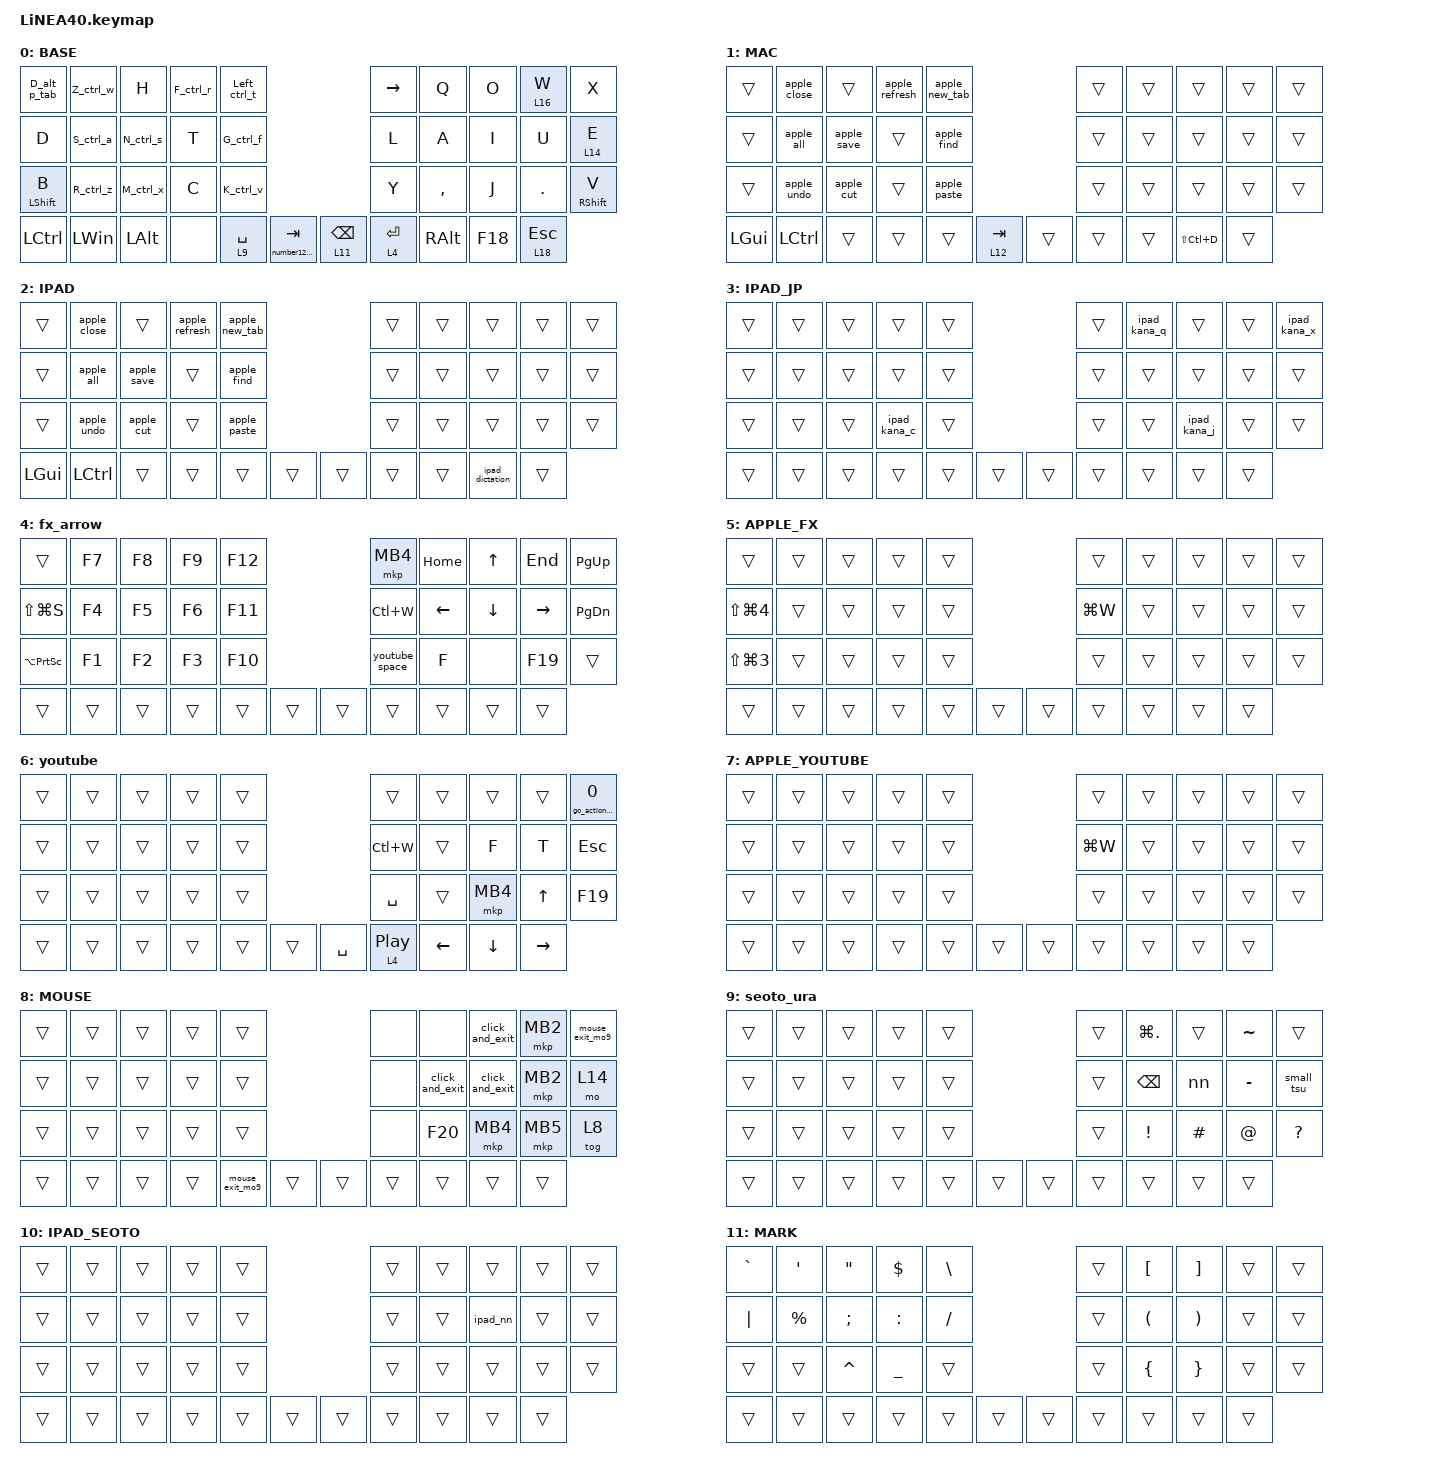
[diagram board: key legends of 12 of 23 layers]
#define ZMK_POINTING_DEFAULT_SCRL_VAL 100

#include <dt-bindings/zmk/input_transform.h>
#include <input/processors.dtsi>
#include <zephyr/dt-bindings/input/input-event-codes.h>
#include <behaviors.dtsi>
#include <dt-bindings/zmk/bt.h>
#include <dt-bindings/zmk/keys.h>
#include <dt-bindings/zmk/outputs.h>
#include <dt-bindings/zmk/pointing.h>

//mouse cursol

&mmv {
    delay-ms = <20>;
    trigger-period-ms = <5>;
    time-to-max-speed-ms = <100>;
    acceleration-exponent = <2>;
};

//mouse scroll

&msc {
    delay-ms = <3>;
    trigger-period-ms = <3>;
    time-to-max-speed-ms = <100>;
    acceleration-exponent = <0>;
};

&lt { flavor = "hold-preferred"; };

&mt { flavor = "balanced"; };

/ {
    input_processors {
        // No remainder tracking: disabled trackball motion must never accumulate.

        zip_trackball_block: zip_trackball_block {
            compatible = "zmk,input-processor-scaler";
            #input-processor-cells = <2>;
            type = <INPUT_EV_REL>;
            codes = <INPUT_REL_X INPUT_REL_Y INPUT_REL_WHEEL INPUT_REL_HWHEEL>;
        };

        zip_wheel_scaler: zip_wheel_scaler {
            compatible = "zmk,input-processor-scaler";
            #input-processor-cells = <2>;
            type = <INPUT_EV_REL>;
            codes = <INPUT_REL_WHEEL>;
            track-remainders;
        };
    };
};

&msc_input_listener {
    speed_up {
        layers = <4 20>;
        input-processors = <&zip_wheel_scaler 3 1>; //スクロールを3倍速にする
    };
};

&trackball_listener {
    // First matching override wins. Do not process the base zip_temp_layer
    // while NUMBER_SCROLL is active, including while fn/arrow keys overlay it.

    number_block {
        layers = <12>;
        input-processors = <&zip_trackball_block 0 1>;
    };

    scroller {
        layers = <14>;
        input-processors =
            // Disable horizontal scrolling; remove this scaler to restore it.,,
            <&zip_x_scaler 0 1>,
            <&zip_xy_transform INPUT_TRANSFORM_Y_INVERT>,
            <&zip_xy_to_scroll_mapper>,
            <&zip_wheel_scaler 1 20>;
    };
};

/ {
    combos {
        compatible = "zmk,combos";

        DeleteKey {
            bindings = <&kp DEL>;
            key-positions = <9 8>;
            layers = <0 12 1 2 13 3>;
        };

        InsertKey {
            bindings = <&kp INS>;
            key-positions = <6 7>;
            layers = <0 1 2 3>;
        };

        IMEON {
            bindings = <&IME_ON_mouseout>;
            key-positions = <17 16>;
            timeout-ms = <80>;
        };

        CenterClick {
            bindings = <&mkp MB3>;
            key-positions = <18 17>;
            layers = <8>;
        };

        IMEOFF {
            bindings = <&IME_OFF_mouseout>;
            key-positions = <13 12>;
            timeout-ms = <80>;
        };

        CtrlEnter {
            bindings = <&kp LC(ENTER)>;
            key-positions = <29 28>;
            layers = <0 1 2 3>;
        };

        esc {
            bindings = <&kp ESCAPE>;
            key-positions = <0 1>;
            layers = <0 22 1 2 3>;
        };

        DeleteKey2 {
            bindings = <&kp DEL>;
            key-positions = <16 9>;
            layers = <0 12 1 2 13 3>;
        };

        window_minimum {
            bindings = <&window_minimum>;
            key-positions = <31 32>;
            layers = <0>;
        };

        apple_window_minimum {
            bindings = <&kp LG(M)>;
            key-positions = <31 32>;
            layers = <1 2 3>;
        };

        CenterClick2 {
            bindings = <&mkp MB3>;
            key-positions = <7 8>;
            layers = <8>;
        };

        to_browsing {
            bindings = <&to2_youtube>;
            key-positions = <38 39 40>;
            layers = <0 8 1 2 3>;
            timeout-ms = <150>;
        };

        L1_home {
            bindings = <&kp HOME>;
            key-positions = <8 9>;
            layers = <4 20 5 21>;
        };

        L1_end {
            bindings = <&kp END>;
            key-positions = <18 19>;
            layers = <4 20 5 21>;
        };

        L1_less {
            bindings = <&kp LESS_THAN>;
            key-positions = <7 16>;
            layers = <4 20 5 21>;
        };

        L1_greater {
            bindings = <&kp GREATER_THAN>;
            key-positions = <7 18>;
            layers = <4 20 5 21>;
        };

        L2_greater {
            bindings = <&kp GREATER_THAN>;
            key-positions = <28 40>;
            layers = <6 7>;
        };

        L2_less {
            bindings = <&kp LESS_THAN>;
            key-positions = <28 38>;
            layers = <6 7>;
        };

        to_browsing2 {
            bindings = <&none>;
            key-positions = <38 39 40>;
            layers = <6 7>;
        };
    };

    behaviors {
        ipad_kana_c: ipad_kana_c {
            compatible = "zmk,behavior-mod-morph";
            #binding-cells = <0>;
            bindings = <&kp K>, <&kp C>;
            mods = <(MOD_LCTL | MOD_LSFT | MOD_LALT | MOD_LGUI |
                      MOD_RCTL | MOD_RSFT | MOD_RALT | MOD_RGUI)>;
            keep-mods = <(MOD_LCTL | MOD_LSFT | MOD_LALT | MOD_LGUI |
                           MOD_RCTL | MOD_RSFT | MOD_RALT | MOD_RGUI)>;
        };

        ipad_kana_x: ipad_kana_x {
            compatible = "zmk,behavior-mod-morph";
            #binding-cells = <0>;
            bindings = <&ipad_romaji_ya>, <&kp X>;
            mods = <(MOD_LCTL | MOD_LSFT | MOD_LALT | MOD_LGUI |
                      MOD_RCTL | MOD_RSFT | MOD_RALT | MOD_RGUI)>;
            keep-mods = <(MOD_LCTL | MOD_LSFT | MOD_LALT | MOD_LGUI |
                           MOD_RCTL | MOD_RSFT | MOD_RALT | MOD_RGUI)>;
        };

        ipad_kana_j: ipad_kana_j {
            compatible = "zmk,behavior-mod-morph";
            #binding-cells = <0>;
            bindings = <&ipad_romaji_yu>, <&kp J>;
            mods = <(MOD_LCTL | MOD_LSFT | MOD_LALT | MOD_LGUI |
                      MOD_RCTL | MOD_RSFT | MOD_RALT | MOD_RGUI)>;
            keep-mods = <(MOD_LCTL | MOD_LSFT | MOD_LALT | MOD_LGUI |
                           MOD_RCTL | MOD_RSFT | MOD_RALT | MOD_RGUI)>;
        };

        ipad_kana_q: ipad_kana_q {
            compatible = "zmk,behavior-mod-morph";
            #binding-cells = <0>;
            bindings = <&ipad_romaji_yo>, <&kp Q>;
            mods = <(MOD_LCTL | MOD_LSFT | MOD_LALT | MOD_LGUI |
                      MOD_RCTL | MOD_RSFT | MOD_RALT | MOD_RGUI)>;
            keep-mods = <(MOD_LCTL | MOD_LSFT | MOD_LALT | MOD_LGUI |
                           MOD_RCTL | MOD_RSFT | MOD_RALT | MOD_RGUI)>;
        };

        apple_paste: apple_paste {
            compatible = "zmk,behavior-mod-morph";
            #binding-cells = <0>;
            bindings = <&kp K>, <&kp LG(V)>;
            mods = <(MOD_LGUI | MOD_RGUI)>;
            keep-mods = <(MOD_LGUI | MOD_RGUI)>;
        };

        apple_cut: apple_cut {
            compatible = "zmk,behavior-mod-morph";
            #binding-cells = <0>;
            bindings = <&kp M>, <&kp LG(X)>;
            mods = <(MOD_LGUI | MOD_RGUI)>;
            keep-mods = <(MOD_LGUI | MOD_RGUI)>;
        };

        apple_undo: apple_undo {
            compatible = "zmk,behavior-mod-morph";
            #binding-cells = <0>;
            bindings = <&kp R>, <&kp LG(Z)>;
            mods = <(MOD_LGUI | MOD_RGUI)>;
            keep-mods = <(MOD_LGUI | MOD_RGUI)>;
        };

        apple_all: apple_all {
            compatible = "zmk,behavior-mod-morph";
            #binding-cells = <0>;
            bindings = <&kp S>, <&kp LG(A)>;
            mods = <(MOD_LGUI | MOD_RGUI)>;
            keep-mods = <(MOD_LGUI | MOD_RGUI)>;
        };

        apple_save: apple_save {
            compatible = "zmk,behavior-mod-morph";
            #binding-cells = <0>;
            bindings = <&kp N>, <&kp LG(S)>;
            mods = <(MOD_LGUI | MOD_RGUI)>;
            keep-mods = <(MOD_LGUI | MOD_RGUI)>;
        };

        apple_new_tab: apple_new_tab {
            compatible = "zmk,behavior-mod-morph";
            #binding-cells = <0>;
            bindings = <&kp LEFT>, <&kp LG(T)>;
            mods = <(MOD_LGUI | MOD_RGUI)>;
            keep-mods = <(MOD_LGUI | MOD_RGUI)>;
        };

        apple_close: apple_close {
            compatible = "zmk,behavior-mod-morph";
            #binding-cells = <0>;
            bindings = <&kp Z>, <&kp LG(W)>;
            mods = <(MOD_LGUI | MOD_RGUI)>;
            keep-mods = <(MOD_LGUI | MOD_RGUI)>;
        };

        apple_refresh: apple_refresh {
            compatible = "zmk,behavior-mod-morph";
            #binding-cells = <0>;
            bindings = <&kp F>, <&kp LG(R)>;
            mods = <(MOD_LGUI | MOD_RGUI)>;
            keep-mods = <(MOD_LGUI | MOD_RGUI)>;
        };

        apple_find: apple_find {
            compatible = "zmk,behavior-mod-morph";
            #binding-cells = <0>;
            bindings = <&kp G>, <&kp LG(F)>;
            mods = <(MOD_LGUI | MOD_RGUI)>;
            keep-mods = <(MOD_LGUI | MOD_RGUI)>;
        };


        W_lt: W_lt {
            compatible = "zmk,behavior-hold-tap";
            label = "W_LT";
            #binding-cells = <2>;
            bindings = <&mo>, <&kp>;

            flavor = "balanced";
            tapping-term-ms = <200>;
        };

        // Keep only left-click available briefly after leaving MOUSE.

        sl_mouse: sticky_layer_for_mouse {
            compatible = "zmk,behavior-sticky-key";
            #binding-cells = <1>;
            bindings = <&mo>;
            release-after-ms = <200>;
            quick-release;
            ignore-modifiers;
        };

        re_kp: sensor_rotate_kp {
            compatible = "zmk,behavior-sensor-rotate-var";
            #sensor-binding-cells = <2>;
            bindings = <&kp>, <&kp>;
        };

        mouse_scrl: mouse_wheel_scrl {
            compatible = "zmk,behavior-sensor-rotate-var";
            #sensor-binding-cells = <2>;
            bindings = <&msc>, <&msc>;

            tap-ms = <20>;
        };

        D_alt_p_tab: D_alt_p_tab {
            compatible = "zmk,behavior-mod-morph";
            label = "D_ALT_P_TAB";
            bindings = <&win_p_tab>, <&kp TAB>;

            #binding-cells = <0>;
            mods = <(MOD_LALT|MOD_RALT)>;
            keep-mods = <(MOD_LALT|MOD_RALT)>;
        };

        win_p_tab: win_p_tab {
            compatible = "zmk,behavior-mod-morph";
            label = "WIN_P_TAB";
            bindings = <&kp P>, <&kp TAB>;

            #binding-cells = <0>;
            mods = <(MOD_RGUI|MOD_LGUI)>;
            keep-mods = <(MOD_LGUI|MOD_RGUI)>;
        };

        K_ctrl_v: K_ctrl_v {
            compatible = "zmk,behavior-mod-morph";
            label = "K_CTRL_V";
            bindings = <&kp K>, <&kp LC(V)>;

            #binding-cells = <0>;
            mods = <(MOD_LCTL)>;
            keep-mods = <(MOD_LCTL)>;
        };

        M_ctrl_x: M_ctrl_x {
            compatible = "zmk,behavior-mod-morph";
            label = "M_CTRL_X";
            bindings = <&kp M>, <&kp LC(X)>;

            #binding-cells = <0>;
            mods = <(MOD_LCTL)>;
            keep-mods = <(MOD_LCTL)>;
        };

        R_ctrl_z: R_ctrl_z {
            compatible = "zmk,behavior-mod-morph";
            label = "R_CTRL_Z";
            bindings = <&kp R>, <&kp LC(Z)>;

            #binding-cells = <0>;
            mods = <(MOD_LCTL)>;
            keep-mods = <(MOD_LCTL)>;
        };

        S_ctrl_a: S_ctrl_a {
            compatible = "zmk,behavior-mod-morph";
            label = "S_CTRL_A";
            bindings = <&kp S>, <&kp LC(A)>;

            #binding-cells = <0>;
            mods = <(MOD_LCTL)>;
            keep-mods = <(MOD_LCTL)>;
        };

        N_ctrl_s: N_ctrl_s {
            compatible = "zmk,behavior-mod-morph";
            label = "N_CTRL_S";
            bindings = <&kp N>, <&kp LC(S)>;

            #binding-cells = <0>;
            mods = <(MOD_LCTL)>;
            keep-mods = <(MOD_LCTL)>;
        };

        Left_ctrl_t: Left_ctrl_t {
            compatible = "zmk,behavior-mod-morph";
            label = "LEFT_CTRL_T";
            bindings = <&kp LEFT>, <&kp LC(T)>;

            #binding-cells = <0>;
            mods = <(MOD_LCTL)>;
            keep-mods = <(MOD_LCTL)>;
        };

        Z_ctrl_w: Z_ctrl_w {
            compatible = "zmk,behavior-mod-morph";
            label = "Z_CTRL_W";
            bindings = <&kp Z>, <&kp LC(W)>;

            #binding-cells = <0>;
            mods = <(MOD_LCTL)>;
            keep-mods = <(MOD_LCTL)>;
        };

        F_ctrl_r: F_ctrl_r {
            compatible = "zmk,behavior-mod-morph";
            label = "F_CTRL_R";
            bindings = <&kp F>, <&kp LC(R)>;

            #binding-cells = <0>;
            mods = <(MOD_LCTL)>;
            keep-mods = <(MOD_LCTL)>;
        };

        G_ctrl_f: G_ctrl_f {
            compatible = "zmk,behavior-mod-morph";
            label = "G_CTRL_F";
            bindings = <&kp G>, <&kp LC(F)>;

            #binding-cells = <0>;
            mods = <(MOD_LCTL)>;
            keep-mods = <(MOD_LCTL)>;
        };

        layer_off: layer_off {
            compatible = "zmk,behavior-toggle-layer";
            label = "LAYER_OFF";
            #binding-cells = <1>;
            toggle-mode = "off";
        };

        layer_on: layer_on {
            compatible = "zmk,behavior-toggle-layer";
            #binding-cells = <1>;
            toggle-mode = "on";
        };

        win_arrow_left: win_arrow_left {
            compatible = "zmk,behavior-mod-morph";
            label = "WIN_ARROW_LEFT";
            bindings = <&win_start_left>, <&kp LEFT>;

            #binding-cells = <0>;
            mods = <(MOD_LGUI)>;
            keep-mods = <(MOD_LGUI)>;
        };

        win_arrow_down: win_arrow_down {
            compatible = "zmk,behavior-mod-morph";
            label = "WIN_ARROW_DOWN";
            bindings = <&win_start_down>, <&kp DOWN>;

            #binding-cells = <0>;
            mods = <(MOD_LGUI)>;
            keep-mods = <(MOD_LGUI)>;
        };

        win_arrow_up: win_arrow_up {
            compatible = "zmk,behavior-mod-morph";
            label = "WIN_ARROW_UP";
            bindings = <&win_start_up>, <&kp UP>;

            #binding-cells = <0>;
            mods = <(MOD_LGUI)>;
            keep-mods = <(MOD_LGUI)>;
        };

        win_arrow_right: win_arrow_right {
            compatible = "zmk,behavior-mod-morph";
            label = "WIN_ARROW_RIGHT";
            bindings = <&win_start_right>, <&kp RIGHT>;

            #binding-cells = <0>;
            mods = <(MOD_LGUI)>;
            keep-mods = <(MOD_LGUI)>;
        };

        number12_lt: number12_lt {
            compatible = "zmk,behavior-hold-tap";
            label = "NUMBER12_LT";
            bindings = <&number12_hold>, <&kp>;

            #binding-cells = <2>;
            tapping-term-ms = <200>;
        };
    };

    macros {
        // A profile choice starts at that device's base. BT2 and BT3 use the Windows base.
        select_profile: select_profile {
            compatible = "zmk,behavior-macro-two-param";
            #binding-cells = <2>;
            wait-ms = <0>;
            tap-ms = <0>;
            bindings =
                <&macro_press>,
                <&macro_param_2to1 &to 0>,
                <&macro_param_1to2 &bt BT_SEL 0>;
        };

        // Clear ordinary layers in descending order. Conditional overlays follow those layers.
        // Keep the Mac/iPad base and iPad Japanese overlays (1–3) active.
        go_action_layer: go_action_layer {
            compatible = "zmk,behavior-macro-one-param";
            #binding-cells = <1>;
            wait-ms = <0>;
            tap-ms = <0>;
            bindings =
                <&macro_press>,
                <&layer_off 22 &layer_off 20 &layer_off 19 &layer_off 18>,
                <&layer_off 16 &layer_off 15 &layer_off 14 &layer_off 12>,
                <&layer_off 11 &layer_off 9 &layer_off 8 &layer_off 6 &layer_off 4>,
                <&macro_param_1to1 &layer_on 0>;
        };

        // Hold MB1 until release for dragging, then return to BASE.

        click_and_exit: click_and_exit {
            compatible = "zmk,behavior-macro";
            #binding-cells = <0>;
            label = "CLICK_AND_EXIT";
            wait-ms = <0>;
            tap-ms = <0>;
            bindings =
                <&macro_press>,
                <&mkp MB1>,
                <&macro_pause_for_release>,
                <&macro_release>,
                <&mkp MB1>,
                <&macro_press>,
                <&layer_off 22 &layer_off 20 &layer_off 19 &layer_off 18>,
                <&layer_off 16 &layer_off 15 &layer_off 14 &layer_off 12>,
                <&layer_off 11 &layer_off 9 &layer_off 8 &layer_off 6 &layer_off 4>,
                <&macro_tap &sl_mouse 19>;
        };

        nn: nn {
            compatible = "zmk,behavior-macro";
            #binding-cells = <0>;
            bindings = <&kp V &kp N>;
            label = "NN";
        };

        // Queue both letters without a wait that would let the next key overtake them.
        ipad_romaji_ya: ipad_romaji_ya {
            compatible = "zmk,behavior-macro";
            #binding-cells = <0>;
            wait-ms = <0>;
            tap-ms = <0>;
            bindings = <&kp Y &kp A>;
        };

        ipad_romaji_yu: ipad_romaji_yu {
            compatible = "zmk,behavior-macro";
            #binding-cells = <0>;
            wait-ms = <0>;
            tap-ms = <0>;
            bindings = <&kp Y &kp U>;
        };

        ipad_romaji_yo: ipad_romaji_yo {
            compatible = "zmk,behavior-macro";
            #binding-cells = <0>;
            wait-ms = <0>;
            tap-ms = <0>;
            bindings = <&kp Y &kp O>;
        };

        ipad_nn: ipad_nn {
            compatible = "zmk,behavior-macro";
            #binding-cells = <0>;
            bindings = <&kp N &kp N>;
        };

        ipad_dictation: ipad_dictation {
            compatible = "zmk,behavior-macro";
            #binding-cells = <0>;
            wait-ms = <30>;
            tap-ms = <30>;
            bindings = <&macro_press &kp GLOBE>,
                       <&macro_tap &kp D>,
                       <&macro_release &kp GLOBE>;
        };

        small_tsu: small_tsu {
            compatible = "zmk,behavior-macro";
            #binding-cells = <0>;
            bindings = <&kp L &kp T &kp U>;
            label = "SMALL_TSU";
        };

        sleep: sleep {
            compatible = "zmk,behavior-macro";
            #binding-cells = <0>;
            bindings = <&kp LG(X) &kp U &kp S>;
            label = "SLEEP";
            wait-ms = <200>;
            tap-ms = <40>;
        };

        IME_ON_mouseout: IME_ON {
            compatible = "zmk,behavior-macro";
            #binding-cells = <0>;
            bindings = <&kp LANG1 &layer_on 3 &go_action_layer 0>;
            label = "IME_ON";
        };

        IME_OFF_mouseout: IME_OFF {
            compatible = "zmk,behavior-macro";
            #binding-cells = <0>;
            bindings = <&layer_off 3 &kp LANGUAGE_2 &go_action_layer 0>;
            label = "IME_OFF";
        };

        window_minimum: window_minimum {
            compatible = "zmk,behavior-macro";
            #binding-cells = <0>;
            bindings = <&kp LA(SPACE) &kp N>;
            label = "WINDOW_MINIMUM";
            wait-ms = <50>;
            tap-ms = <50>;
        };

        mouse_exit_mo9: mouse_exit_mo9 {
            compatible = "zmk,behavior-macro";
            #binding-cells = <0>;
            bindings =
                <&layer_off 8>,
                <&macro_press>,
                <&mo 15>,
                <&macro_pause_for_release>,
                <&macro_release>,
                <&mo 15>,
                <&macro_tap>,
                <&layer_off 8>;

            label = "MOUSE_EXIT_MO9";
            wait-ms = <0>;
            tap-ms = <0>;
        };

        win_start_left: win_start_left {
            compatible = "zmk,behavior-macro";
            #binding-cells = <0>;
            bindings = <&macro_press>, <&kp LEFT_GUI>, <&macro_tap>, <&kp LEFT>;

            label = "WIN_START_LEFT";
            wait-ms = <30>;
            tap-ms = <30>;
        };

        win_start_down: win_start_down {
            compatible = "zmk,behavior-macro";
            #binding-cells = <0>;
            bindings = <&macro_press>, <&kp LEFT_GUI>, <&macro_tap>, <&kp DOWN>;

            label = "WIN_START_DOWN";
            wait-ms = <30>;
            tap-ms = <30>;
        };

        win_start_up: win_start_up {
            compatible = "zmk,behavior-macro";
            #binding-cells = <0>;
            bindings = <&macro_press>, <&kp LEFT_GUI>, <&macro_tap>, <&kp UP>;

            label = "WIN_START_UP";
            wait-ms = <30>;
            tap-ms = <30>;
        };

        win_start_right: win_start_right {
            compatible = "zmk,behavior-macro";
            #binding-cells = <0>;
            bindings =
                <&macro_press>,
                <&kp LEFT_GUI>,
                <&macro_tap>,
                <&kp RIGHT>;

            label = "WIN_START_RIGHT";
            wait-ms = <30>;
            tap-ms = <30>;
        };

        number12_hold: number12_hold {
            compatible = "zmk,behavior-macro";
            #binding-cells = <0>;
            bindings =
                <&macro_press>,
                <&mo 12>,
                <&macro_pause_for_release>,
                <&macro_release>,
                <&kp LEFT_GUI &mo 12>;

            label = "NUMBER12_HOLD";
            wait-ms = <0>;
            tap-ms = <0>;
        };

        youtube_space: youtube_space {
            compatible = "zmk,behavior-macro";
            #binding-cells = <0>;
            bindings = <&kp F19 &kp SPACE>;
            label = "YOUTUBE_SPACE";
            wait-ms = <250>;
            tap-ms = <40>;
        };

        to2_youtube: to2_youtube {
            compatible = "zmk,behavior-macro";
            #binding-cells = <0>;
            bindings =
                <&macro_press>,
                <&layer_off 22 &layer_off 20 &layer_off 19 &layer_off 18>,
                <&layer_off 16 &layer_off 15 &layer_off 14 &layer_off 12>,
                <&layer_off 11 &layer_off 9 &layer_off 8 &layer_off 6 &layer_off 4>,
                <&layer_on 6>,
                <&macro_tap &kp F19>;
            label = "TO2_YOUTUBE";
        };
    };

    conditional_layers {
        compatible = "zmk,conditional-layers";

        // Keep the Japanese overlay only when explicitly enabled and iPad is the base.
        // The shared IME combo can then be used even while a mouse layer is active.
        ipad_japanese_only {
            if-layers = <2 3>;
            then-layer = <3>;
        };

        mac_apple_fx {
            if-layers = <1 4>;
            then-layer = <5>;
        };

        ipad_apple_fx {
            if-layers = <2 4>;
            then-layer = <5>;
        };

        mac_apple_youtube {
            if-layers = <1 6>;
            then-layer = <7>;
        };

        ipad_apple_youtube {
            if-layers = <2 6>;
            then-layer = <7>;
        };

        mac_apple_browser {
            if-layers = <1 16>;
            then-layer = <17>;
        };

        ipad_apple_browser {
            if-layers = <2 16>;
            then-layer = <17>;
        };

        mac_apple_fx_number {
            if-layers = <1 20>;
            then-layer = <21>;
        };

        ipad_apple_fx_number {
            if-layers = <2 20>;
            then-layer = <21>;
        };

        ipad_seoto {
            if-layers = <2 9>;
            then-layer = <10>;
        };

        mac_number {
            if-layers = <1 12>;
            then-layer = <13>;
        };
    };

    keymap {
        compatible = "zmk,keymap";

        default_layer {
            display-name = "BASE";
            bindings = <
&D_alt_p_tab      &Z_ctrl_w     &kp H         &F_ctrl_r  &Left_ctrl_t                                        &kp RIGHT    &kp Q      &kp O          &W_lt 16 W  &kp X
&kp D             &S_ctrl_a     &N_ctrl_s     &kp T      &G_ctrl_f                                           &kp L        &kp A      &kp I          &kp U       &lt 14 E
&mt LEFT_SHIFT B  &R_ctrl_z     &M_ctrl_x     &kp C      &K_ctrl_v                                           &kp Y        &kp COMMA  &kp J          &kp DOT     &mt RIGHT_SHIFT V
&kp LCTRL         &kp LEFT_WIN  &kp LEFT_ALT  &none      &lt 9 SPACE   &number12_lt 0 TAB    &lt 11 BACKSPACE  &lt 4 ENTER             &kp RIGHT_ALT  &kp F18     &lt 18 ESC
            >;

            sensor-bindings = <&mouse_scrl SCRL_DOWN SCRL_UP>;
        };

        mac_base {
            display-name = "MAC";
            bindings = <
                &trans  &apple_close   &trans        &apple_refresh  &apple_new_tab    &trans  &trans  &trans  &trans  &trans
                &trans  &apple_all     &apple_save   &trans          &apple_find       &trans  &trans  &trans  &trans  &trans
                &trans  &apple_undo    &apple_cut    &trans          &apple_paste      &trans  &trans  &trans  &trans  &trans
                &kp LGUI &kp LCTRL     &trans        &trans          &trans  &lt 12 TAB  &trans  &trans  &trans  &kp LS(LC(D))  &trans
            >;
        };

        ipad_base {
            display-name = "IPAD";
            bindings = <
                &trans  &apple_close   &trans        &apple_refresh  &apple_new_tab    &trans  &trans  &trans  &trans  &trans
                &trans  &apple_all     &apple_save   &trans          &apple_find       &trans  &trans  &trans  &trans  &trans
                &trans  &apple_undo    &apple_cut    &trans          &apple_paste      &trans  &trans  &trans  &trans  &trans
                &kp LGUI &kp LCTRL     &trans        &trans          &trans  &trans  &trans  &trans  &trans  &ipad_dictation  &trans
            >;
        };

        ipad_japanese {
            display-name = "IPAD_JP";
            bindings = <
                &trans  &trans  &trans  &trans         &trans  &trans  &ipad_kana_q  &trans        &trans  &ipad_kana_x
                &trans  &trans  &trans  &trans         &trans  &trans  &trans        &trans        &trans  &trans
                &trans  &trans  &trans  &ipad_kana_c   &trans  &trans  &trans        &ipad_kana_j  &trans  &trans
                &trans  &trans  &trans  &trans         &trans  &trans  &trans        &trans        &trans  &trans  &trans
            >;
        };

        fx_arrow {
            display-name = "fx_arrow";
            bindings = <
&trans               &kp F7  &kp F8  &kp F9  &kp F12                    &mkp MB4   &kp HOME        &kp UP_ARROW    &kp END          &kp PAGE_UP
&kp LS(LG(S))        &kp F4  &kp F5  &kp F6  &kp F11                    &kp LC(W)  &kp LEFT_ARROW  &kp DOWN_ARROW  &kp RIGHT_ARROW  &kp PAGE_DOWN
&kp LA(PRINTSCREEN)  &kp F1  &kp F2  &kp F3  &kp F10                    &youtube_space  &kp F           &none           &kp F19          &trans
&trans               &trans  &trans  &trans  &trans   &trans    &trans  &trans                     &trans          &trans           &trans
            >;

            sensor-bindings = <&mouse_scrl SCRL_RIGHT SCRL_LEFT>;
        };

        apple_fx_arrow {
            display-name = "APPLE_FX";
            bindings = <
                &trans             &trans  &trans  &trans  &trans     &trans  &trans  &trans  &trans  &trans
                &kp LS(LG(N4))     &trans  &trans  &trans  &trans     &kp LG(W)  &trans  &trans  &trans  &trans
                &kp LS(LG(N3))     &trans  &trans  &trans  &trans     &trans  &trans  &trans  &trans  &trans
                &trans             &trans  &trans  &trans  &trans  &trans  &trans  &trans  &trans  &trans  &trans
            >;
        };

        youtube {
            display-name = "youtube";
            bindings = <
&trans  &trans  &trans  &trans  &trans                       &trans              &trans  &trans          &trans          &go_action_layer 0
&trans  &trans  &trans  &trans  &trans                       &kp LC(W)           &trans  &kp F           &kp T           &kp ESCAPE
&trans  &trans  &trans  &trans  &trans                       &kp SPACE           &trans  &mkp MB4        &kp UP_ARROW    &kp F19
&trans  &trans  &trans  &trans  &trans  &trans    &kp SPACE  &lt 4 C_PLAY_PAUSE          &kp LEFT_ARROW  &kp DOWN_ARROW  &kp RIGHT_ARROW
            >;

            // Keep vertical scrolling when entering the function layer from YouTube.
            sensor-bindings = <&mouse_scrl SCRL_DOWN SCRL_UP>;
        };

        apple_youtube {
            display-name = "APPLE_YOUTUBE";
            bindings = <
                &trans  &trans  &trans  &trans  &trans  &trans  &trans  &trans  &trans  &trans
                &trans  &trans  &trans  &trans  &trans  &kp LG(W)  &trans  &trans  &trans  &trans
                &trans  &trans  &trans  &trans  &trans  &trans  &trans  &trans  &trans  &trans
                &trans  &trans  &trans  &trans  &trans  &trans  &trans  &trans  &trans  &trans  &trans
            >;
        };

        mouse {
            display-name = "MOUSE";
            bindings = <
&trans  &trans  &trans  &trans  &trans                             &none   &none            &click_and_exit  &mkp MB2  &mouse_exit_mo9
&trans  &trans  &trans  &trans  &trans                             &none   &click_and_exit  &click_and_exit  &mkp MB2  &mo 14
&trans  &trans  &trans  &trans  &trans                             &none   &kp F20          &mkp MB4         &mkp MB5  &tog 8
&trans  &trans  &trans  &trans  &mouse_exit_mo9  &trans    &trans  &trans                   &trans           &trans    &trans
            >;
        };

        seoto_ura {
            display-name = "seoto_ura";
            bindings = <
&trans  &trans  &trans  &trans  &trans                    &trans  &kp LG(PERIOD)   &trans    &kp TILDE    &trans
&trans  &trans  &trans  &trans  &trans                    &trans  &kp BACKSPACE    &nn       &kp MINUS    &small_tsu
&trans  &trans  &trans  &trans  &trans                    &trans  &kp EXCLAMATION  &kp HASH  &kp AT_SIGN  &kp QMARK
&trans  &trans  &trans  &trans  &trans  &trans    &trans  &trans                   &trans    &trans       &trans
            >;
        };

        ipad_seoto {
            display-name = "IPAD_SEOTO";
            bindings = <
                &trans  &trans  &trans  &trans  &trans  &trans  &trans  &trans  &trans  &trans
                &trans  &trans  &trans  &trans  &trans  &trans  &trans  &ipad_nn  &trans  &trans
                &trans  &trans  &trans  &trans  &trans  &trans  &trans  &trans  &trans  &trans
                &trans  &trans  &trans  &trans  &trans  &trans  &trans  &trans  &trans  &trans  &trans
            >;
        };

        mark {
            display-name = "MARK";
            bindings = <
&kp GRAVE  &kp SINGLE_QUOTE  &kp DOUBLE_QUOTES  &kp DOLLAR  &kp BACKSLASH                    &trans  &kp LEFT_BRACKET      &kp RIGHT_BRACKET      &trans  &trans
&kp PIPE   &kp PERCENT       &kp SEMI           &kp COLON   &kp SLASH                        &trans  &kp LEFT_PARENTHESIS  &kp RIGHT_PARENTHESIS  &trans  &trans
&trans     &trans            &kp CARET          &kp UNDER   &trans                           &trans  &kp LEFT_BRACE        &kp RIGHT_BRACE        &trans  &trans
&trans     &trans            &trans             &trans      &trans         &trans    &trans  &trans                        &trans                 &trans  &trans
            >;

            sensor-bindings = <&re_kp C_VOLUME_DOWN C_VOLUME_UP>;
        };

        number_scroll {
            display-name = "NUMBER_SCROLL";
            bindings = <
&trans    &kp LC(LG(LEFT_ARROW))  &win_arrow_up    &kp LC(LG(RIGHT_ARROW))  &trans                    &kp KP_SLASH     &kp NUMBER_7  &kp NUMBER_8  &kp NUMBER_9  &kp KP_MINUS
&trans    &win_arrow_left         &win_arrow_down  &win_arrow_right         &trans                    &kp KP_MULTIPLY  &kp NUMBER_4  &kp NUMBER_5  &kp NUMBER_6  &kp KP_PLUS
&kp HOME  &kp PAGE_DOWN           &kp END          &kp PAGE_UP              &trans                    &kp UNDER        &kp NUMBER_1  &kp NUMBER_2  &kp NUMBER_3  &kp ENTER
&trans    &trans                  &trans           &trans                   &trans  &trans    &trans  &lt 20 NUMBER_0                &kp NUMBER_0  &kp DOT       &kp EQUAL
            >;

            sensor-bindings = <&inc_dec_kp DOWN_ARROW UP_ARROW>;
        };

        // The four placement chords are assigned in macOS App Shortcuts.
        mac_number {
            display-name = "MAC_NUMBER";
            bindings = <
                &trans  &kp LC(LEFT)  &kp LC(LA(LG(UP)))  &kp LC(RIGHT)  &trans  &trans  &trans  &trans  &trans  &trans
                &trans  &kp LC(LA(LG(LEFT)))  &kp LC(LA(LG(DOWN)))  &kp LC(LA(LG(RIGHT)))  &trans  &trans  &trans  &trans  &trans  &trans
                &trans  &trans  &trans  &trans  &trans  &trans  &trans  &trans  &trans  &trans
                &trans  &trans  &trans  &trans  &trans  &trans  &trans  &trans  &trans  &trans  &trans
            >;
        };

        trackball_scroll {
            display-name = "trackball_scroll";
            bindings = <
&trans  &trans  &trans  &trans  &trans                    &trans  &trans  &trans  &trans  &trans
&trans  &trans  &trans  &trans  &trans                    &trans  &trans  &trans  &trans  &trans
&trans  &trans  &trans  &trans  &trans                    &trans  &trans  &trans  &trans  &trans
&trans  &trans  &trans  &trans  &trans  &trans    &trans  &trans          &trans  &trans  &trans
            >;
        };

        mouse_slow_1to {
            display-name = "mouse_slow_1to";
            bindings = <
&trans  &trans  &trans  &trans  &trans                    &trans  &trans  &trans  &trans  &trans
&trans  &trans  &trans  &trans  &trans                    &trans  &trans  &trans  &trans  &trans
&trans  &trans  &trans  &trans  &trans                    &trans  &trans  &trans  &trans  &trans
&trans  &trans  &trans  &trans  &trans  &trans    &trans  &trans          &trans  &trans  &trans
            >;
        };

        browser {
            display-name = "browser";
            bindings = <
&trans  &trans  &trans  &trans  &trans                    &trans  &kp LC(W)      &kp LS(LC(TAB))  &trans  &kp LC(TAB)
&trans  &trans  &trans  &trans  &trans                    &trans  &kp LS(LC(T))  &trans           &trans  &trans
&trans  &trans  &trans  &trans  &trans                    &trans  &trans         &trans           &trans  &trans
&trans  &trans  &trans  &trans  &trans  &trans    &trans  &trans                 &trans           &trans  &trans
            >;
        };

        apple_browser {
            display-name = "APPLE_BROWSER";
            bindings = <
                &trans  &trans  &trans  &trans  &trans  &trans  &kp LG(W)  &trans  &trans  &trans
                &trans  &trans  &trans  &trans  &trans  &trans  &kp LS(LG(T))  &trans  &trans  &trans
                &trans  &trans  &trans  &trans  &trans  &trans  &trans  &trans  &trans  &trans
                &trans  &trans  &trans  &trans  &trans  &trans  &trans  &trans  &trans  &trans  &trans
            >;
        };

        wireless {
            display-name = "WIRELESS";
            bindings = <
&select_profile 0 0    &select_profile 1 1  &select_profile 2 0  &select_profile 3 0  &select_profile 4 2                              &select_profile 0 0    &select_profile 1 1  &select_profile 2 0  &select_profile 3 0   &select_profile 4 2
&trans          &trans        &trans        &out OUT_BLE  &out OUT_USB                              &trans          &trans        &trans        &bt BT_DISC 4  &sleep
&bt BT_CLR      &trans        &trans        &trans        &trans                                    &trans          &trans        &trans        &trans         &go_action_layer 12
&bt BT_CLR_ALL  &trans        &trans        &trans        &trans        &bootloader    &bootloader  &studio_unlock                &trans        &trans         &trans
            >;

            sensor-bindings = <&inc_dec_kp RIGHT_ARROW LEFT_ARROW>;
        };

        click_repeat {
            display-name = "CLICK_REPEAT";
            bindings = <
&trans  &trans  &trans  &trans  &trans                    &trans  &trans           &click_and_exit  &trans  &trans
&trans  &trans  &trans  &trans  &trans                    &trans  &click_and_exit  &click_and_exit  &trans  &trans
&trans  &trans  &trans  &trans  &trans                    &trans  &trans           &trans           &trans  &trans
&trans  &trans  &trans  &trans  &trans  &trans    &trans  &trans                   &trans           &trans  &trans
            >;
        };

        fx_arrow_number {
            display-name = "fx_arrow_number";
            bindings = <
&trans               &kp F7  &kp F8  &kp F9  &kp F12                    &mkp MB4   &kp HOME        &kp UP_ARROW    &kp END          &kp PAGE_UP
&kp LS(LG(S))        &kp F4  &kp F5  &kp F6  &kp F11                    &kp LC(W)  &kp LEFT_ARROW  &kp DOWN_ARROW  &kp RIGHT_ARROW  &kp PAGE_DOWN
&kp LA(PRINTSCREEN)  &kp F1  &kp F2  &kp F3  &kp F10                    &kp SPACE  &kp F           &none           &kp F19          &trans
&trans               &trans  &trans  &trans  &trans   &trans    &trans  &trans                     &trans          &trans           &trans
            >;

            sensor-bindings = <&mouse_scrl SCRL_DOWN SCRL_UP>;
        };

        apple_fx_number {
            display-name = "APPLE_FX_NUMBER";
            bindings = <
                &trans             &trans  &trans  &trans  &trans     &trans  &trans  &trans  &trans  &trans
                &kp LS(LG(N4))     &trans  &trans  &trans  &trans     &kp LG(W)  &trans  &trans  &trans  &trans
                &kp LS(LG(N3))     &trans  &trans  &trans  &trans     &trans  &trans  &trans  &trans  &trans
                &trans             &trans  &trans  &trans  &trans  &trans  &trans  &trans  &trans  &trans  &trans
            >;
        };

        reserved_2 {
            display-name = "RESERVED_2";
            bindings = <
&trans  &trans  &trans  &trans  &trans                    &trans  &trans  &trans  &trans  &trans
&trans  &trans  &trans  &trans  &trans                    &trans  &trans  &trans  &trans  &trans
&trans  &trans  &trans  &trans  &trans                    &trans  &trans  &trans  &trans  &trans
&trans  &trans  &trans  &trans  &trans  &trans    &trans  &trans          &trans  &trans  &trans
            >;
        };
    };
};
